VERSION ""

NS_ :

BS_:

BU_: SBG C125

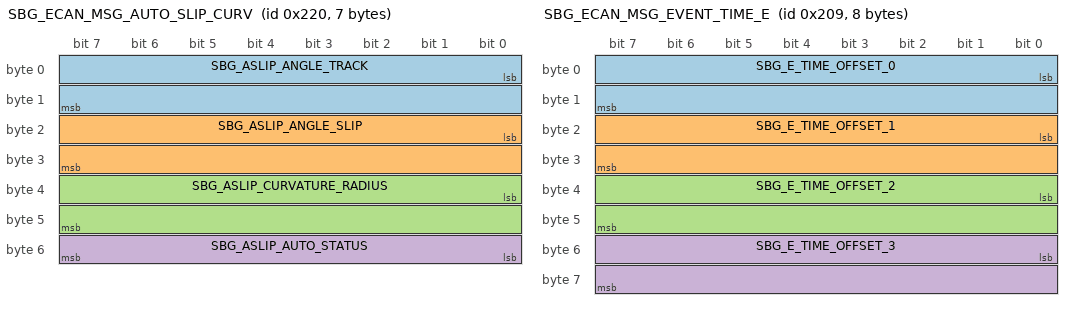
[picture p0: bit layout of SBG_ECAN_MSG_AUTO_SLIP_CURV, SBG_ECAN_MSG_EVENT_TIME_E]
BO_ 544 SBG_ECAN_MSG_AUTO_SLIP_CURV: 7 SBG
 SG_ SBG_ASLIP_ANGLE_TRACK : 0|16@1- (0.0001,0) [-3.2768|3.2767] "rad" C125
 SG_ SBG_ASLIP_ANGLE_SLIP : 16|16@1- (0.0001,0) [-3.2768|3.2767] "rad" C125
 SG_ SBG_ASLIP_CURVATURE_RADIUS : 32|16@1+ (0.01,0) [0|655.35] "m" C125
 SG_ SBG_ASLIP_AUTO_STATUS : 48|8@1+ (1,0) [0|255] "" C125

BO_ 521 SBG_ECAN_MSG_EVENT_TIME_E: 8 SBG
 SG_ SBG_E_TIME_OFFSET_0 : 0|16@1+ (1,0) [0|65535] "µs" Vector__XXX
 SG_ SBG_E_TIME_OFFSET_1 : 16|16@1+ (1,0) [0|65535] "µs" Vector__XXX
 SG_ SBG_E_TIME_OFFSET_2 : 32|16@1+ (1,0) [0|65535] "µs" Vector__XXX
 SG_ SBG_E_TIME_OFFSET_3 : 48|16@1+ (1,0) [0|65535] "µs" Vector__XXX

BO_ 520 SBG_ECAN_MSG_EVENT_INFO_E: 8 SBG
 SG_ SBG_E_TIME_STAMP : 0|32@1+ (1,0) [0|4294970000] "µs" Vector__XXX
 SG_ SBG_E_STATUS : 32|16@1+ (1,0) [0|65535] "" Vector__XXX

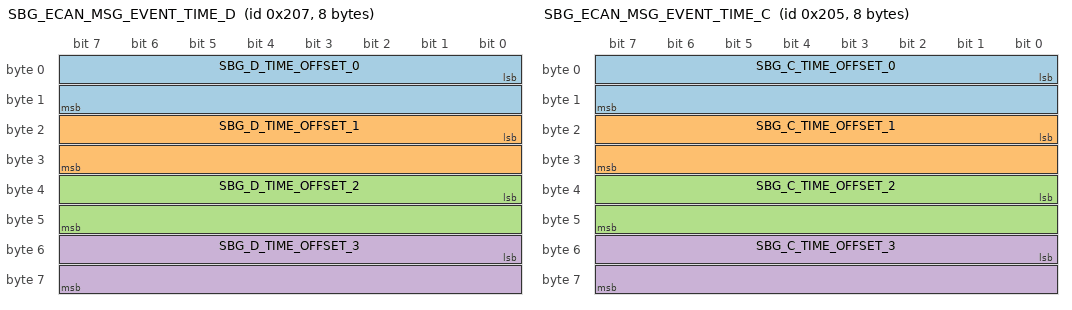
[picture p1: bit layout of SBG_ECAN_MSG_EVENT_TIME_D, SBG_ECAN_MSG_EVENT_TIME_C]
BO_ 519 SBG_ECAN_MSG_EVENT_TIME_D: 8 SBG
 SG_ SBG_D_TIME_OFFSET_0 : 0|16@1+ (1,0) [0|65535] "µs" Vector__XXX
 SG_ SBG_D_TIME_OFFSET_1 : 16|16@1+ (1,0) [0|65535] "µs" Vector__XXX
 SG_ SBG_D_TIME_OFFSET_2 : 32|16@1+ (1,0) [0|65535] "µs" Vector__XXX
 SG_ SBG_D_TIME_OFFSET_3 : 48|16@1+ (1,0) [0|65535] "µs" Vector__XXX

BO_ 518 SBG_ECAN_MSG_EVENT_INFO_D: 8 SBG
 SG_ SBG_D_TIME_STAMP : 0|32@1+ (1,0) [0|4294970000] "µs" Vector__XXX
 SG_ SBG_D_STATUS : 32|16@1+ (1,0) [0|65535] "" Vector__XXX

BO_ 517 SBG_ECAN_MSG_EVENT_TIME_C: 8 SBG
 SG_ SBG_C_TIME_OFFSET_0 : 0|16@1+ (1,0) [0|65535] "µs" Vector__XXX
 SG_ SBG_C_TIME_OFFSET_1 : 16|16@1+ (1,0) [0|65535] "µs" Vector__XXX
 SG_ SBG_C_TIME_OFFSET_2 : 32|16@1+ (1,0) [0|65535] "µs" Vector__XXX
 SG_ SBG_C_TIME_OFFSET_3 : 48|16@1+ (1,0) [0|65535] "µs" Vector__XXX

BO_ 516 SBG_ECAN_MSG_EVENT_INFO_C: 8 SBG
 SG_ SBG_C_TIME_STAMP : 0|32@1+ (1,0) [0|4294970000] "µs" Vector__XXX
 SG_ SBG_C_STATUS : 32|16@1+ (1,0) [0|65535] "" Vector__XXX

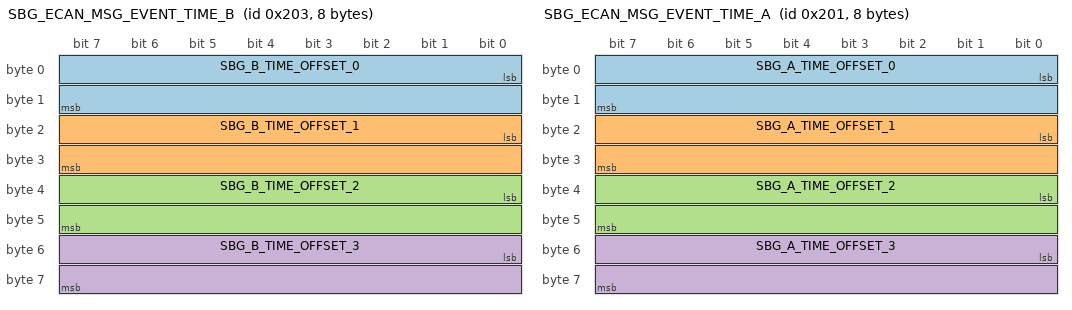
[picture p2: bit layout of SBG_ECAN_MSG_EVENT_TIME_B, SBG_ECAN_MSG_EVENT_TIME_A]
BO_ 515 SBG_ECAN_MSG_EVENT_TIME_B: 8 SBG
 SG_ SBG_B_TIME_OFFSET_0 : 0|16@1+ (1,0) [0|65535] "µs" Vector__XXX
 SG_ SBG_B_TIME_OFFSET_1 : 16|16@1+ (1,0) [0|65535] "µs" Vector__XXX
 SG_ SBG_B_TIME_OFFSET_2 : 32|16@1+ (1,0) [0|65535] "µs" Vector__XXX
 SG_ SBG_B_TIME_OFFSET_3 : 48|16@1+ (1,0) [0|65535] "µs" Vector__XXX

BO_ 514 SBG_ECAN_MSG_EVENT_INFO_B: 8 SBG
 SG_ SBG_B_TIME_STAMP : 0|32@1+ (1,0) [0|4294970000] "µs" Vector__XXX
 SG_ SBG_B_STATUS : 32|16@1+ (1,0) [0|65535] "" Vector__XXX

BO_ 513 SBG_ECAN_MSG_EVENT_TIME_A: 8 SBG
 SG_ SBG_A_TIME_OFFSET_0 : 0|16@1+ (1,0) [0|65535] "µs" Vector__XXX
 SG_ SBG_A_TIME_OFFSET_1 : 16|16@1+ (1,0) [0|65535] "µs" Vector__XXX
 SG_ SBG_A_TIME_OFFSET_2 : 32|16@1+ (1,0) [0|65535] "µs" Vector__XXX
 SG_ SBG_A_TIME_OFFSET_3 : 48|16@1+ (1,0) [0|65535] "µs" Vector__XXX

BO_ 512 SBG_ECAN_MSG_EVENT_INFO_A: 8 SBG
 SG_ SBG_A_TIME_STAMP : 0|32@1+ (1,0) [0|4294970000] "µs" Vector__XXX
 SG_ SBG_A_STATUS : 32|16@1+ (1,0) [0|65535] "" Vector__XXX

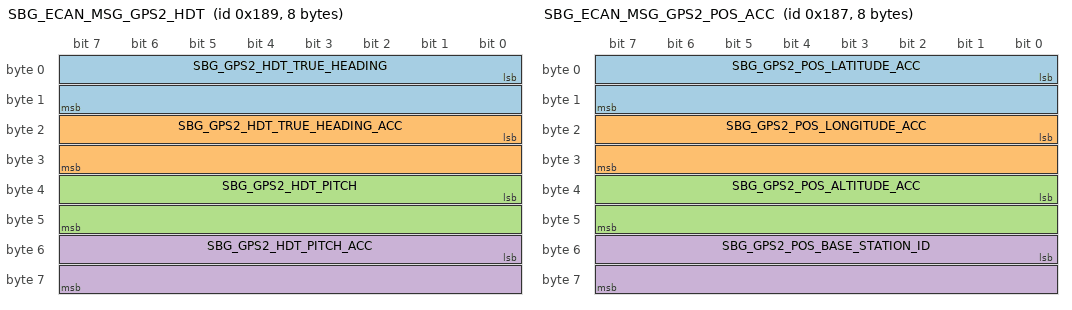
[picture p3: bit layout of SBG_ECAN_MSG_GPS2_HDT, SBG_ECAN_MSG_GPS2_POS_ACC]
BO_ 393 SBG_ECAN_MSG_GPS2_HDT: 8 SBG
 SG_ SBG_GPS2_HDT_TRUE_HEADING : 0|16@1+ (0.01,0) [0|655.35] "°" Vector__XXX
 SG_ SBG_GPS2_HDT_TRUE_HEADING_ACC : 16|16@1+ (0.01,0) [0|655.35] "°" Vector__XXX
 SG_ SBG_GPS2_HDT_PITCH : 32|16@1- (0.01,0) [-327.68|327.67] "°" Vector__XXX
 SG_ SBG_GPS2_HDT_PITCH_ACC : 48|16@1+ (0.01,0) [0|655.35] "°" Vector__XXX

BO_ 392 SBG_ECAN_MSG_GPS2_HDT_INFO: 6 SBG
 SG_ SBG_GPS2_HDT_TIME_STAMP : 0|32@1+ (1,0) [0|4294970000] "µs" Vector__XXX
 SG_ SBG_GPS2_HDT_STATUS : 32|16@1+ (1,0) [0|65535] "" Vector__XXX

BO_ 391 SBG_ECAN_MSG_GPS2_POS_ACC: 8 SBG
 SG_ SBG_GPS2_POS_LATITUDE_ACC : 0|16@1+ (0.01,0) [0|655.35] "m" Vector__XXX
 SG_ SBG_GPS2_POS_LONGITUDE_ACC : 16|16@1+ (0.01,0) [0|655.35] "m" Vector__XXX
 SG_ SBG_GPS2_POS_ALTITUDE_ACC : 32|16@1+ (0.01,0) [0|655.35] "m" Vector__XXX
 SG_ SBG_GPS2_POS_BASE_STATION_ID : 48|16@1+ (1,0) [0|65535] "" Vector__XXX

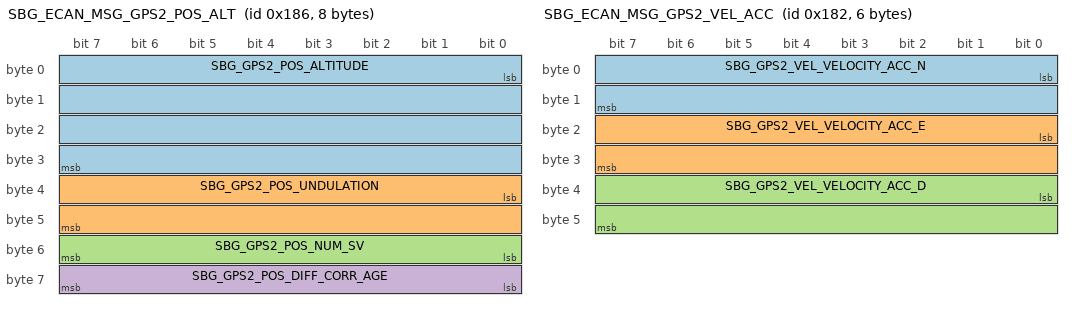
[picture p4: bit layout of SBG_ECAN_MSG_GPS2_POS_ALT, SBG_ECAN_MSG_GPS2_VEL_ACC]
BO_ 390 SBG_ECAN_MSG_GPS2_POS_ALT: 8 SBG
 SG_ SBG_GPS2_POS_ALTITUDE : 0|32@1- (0.001,0) [-2147480|2147480] "m" Vector__XXX
 SG_ SBG_GPS2_POS_UNDULATION : 32|16@1- (0.005,0) [-163.84|163.835] "m" Vector__XXX
 SG_ SBG_GPS2_POS_NUM_SV : 48|8@1+ (1,0) [0|255] "" Vector__XXX
 SG_ SBG_GPS2_POS_DIFF_CORR_AGE : 56|8@1+ (1,0) [0|255] "s" Vector__XXX

BO_ 389 SBG_ECAN_MSG_GPS2_POS: 8 SBG
 SG_ SBG_GPS2_POS_LATITUDE : 0|32@1- (0.0000001,0) [-214.7483648|214.7483647] "°" Vector__XXX
 SG_ SBG_GPS2_POS_LONGITUDE : 32|32@1- (0.0000001,0) [-214.7483648|214.7483647] "°" Vector__XXX

BO_ 388 SBG_ECAN_MSG_GPS2_POS_INFO: 8 SBG
 SG_ SGB_GPS2_POS_TIME_STAMP : 0|32@1+ (1,0) [0|4294970000] "µs" Vector__XXX
 SG_ SBG_GPS2_POS_STATUS : 32|32@1+ (1,0) [0|4294970000] "" Vector__XXX

BO_ 387 SBG_ECAN_MSG_GPS2_VEL_COURSE: 4 SBG
 SG_ SBG_GPS2_VEL_COURSE : 0|16@1+ (0.01,0) [0|655.35] "°" Vector__XXX
 SG_ SBG_GPS2_VEL_COURSE_ACC : 16|16@1+ (0.01,0) [0|655.35] "°" Vector__XXX

BO_ 386 SBG_ECAN_MSG_GPS2_VEL_ACC: 6 SBG
 SG_ SBG_GPS2_VEL_VELOCITY_ACC_N : 0|16@1- (0.01,0) [-327.68|327.67] "m.s-1" Vector__XXX
 SG_ SBG_GPS2_VEL_VELOCITY_ACC_E : 16|16@1- (0.01,0) [-327.68|327.67] "m.s-1" Vector__XXX
 SG_ SBG_GPS2_VEL_VELOCITY_ACC_D : 32|16@1- (0.01,0) [-327.68|327.67] "m.s-1" Vector__XXX

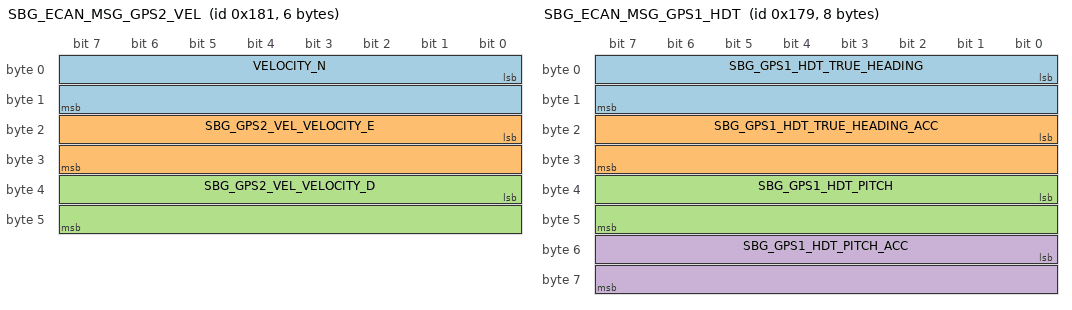
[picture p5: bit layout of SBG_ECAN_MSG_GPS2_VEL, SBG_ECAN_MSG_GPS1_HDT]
BO_ 385 SBG_ECAN_MSG_GPS2_VEL: 6 SBG
 SG_ VELOCITY_N : 0|16@1- (0.01,0) [-327.68|327.67] "m.s-1" Vector__XXX
 SG_ SBG_GPS2_VEL_VELOCITY_E : 16|16@1- (0.01,0) [-327.68|327.67] "m.s-1" Vector__XXX
 SG_ SBG_GPS2_VEL_VELOCITY_D : 32|16@1- (0.01,0) [-327.68|327.67] "m.s-1" Vector__XXX

BO_ 384 SBG_ECAN_MSG_GPS2_VEL_INFO: 8 SBG
 SG_ SBG_GPS2_VEL_TIME_STAMP : 0|32@1+ (1,0) [0|4294970000] "µs" Vector__XXX
 SG_ SBG_GPS2_VEL_STATUS : 32|32@1+ (1,0) [0|4294970000] "" Vector__XXX

BO_ 377 SBG_ECAN_MSG_GPS1_HDT: 8 SBG
 SG_ SBG_GPS1_HDT_TRUE_HEADING : 0|16@1+ (0.01,0) [0|655.35] "°" Vector__XXX
 SG_ SBG_GPS1_HDT_TRUE_HEADING_ACC : 16|16@1+ (0.01,0) [0|655.35] "°" Vector__XXX
 SG_ SBG_GPS1_HDT_PITCH : 32|16@1- (0.01,0) [-327.68|327.67] "°" Vector__XXX
 SG_ SBG_GPS1_HDT_PITCH_ACC : 48|16@1+ (0.01,0) [0|655.35] "°" Vector__XXX

BO_ 376 SBG_ECAN_MSG_GPS1_HDT_INFO: 6 SBG
 SG_ SBG_GPS1_HDT_TIME_STAMP : 0|32@1+ (1,0) [0|4294970000] "µs" Vector__XXX
 SG_ SBG_GPS1_HDT_STATUS : 32|16@1+ (1,0) [0|65535] "" Vector__XXX

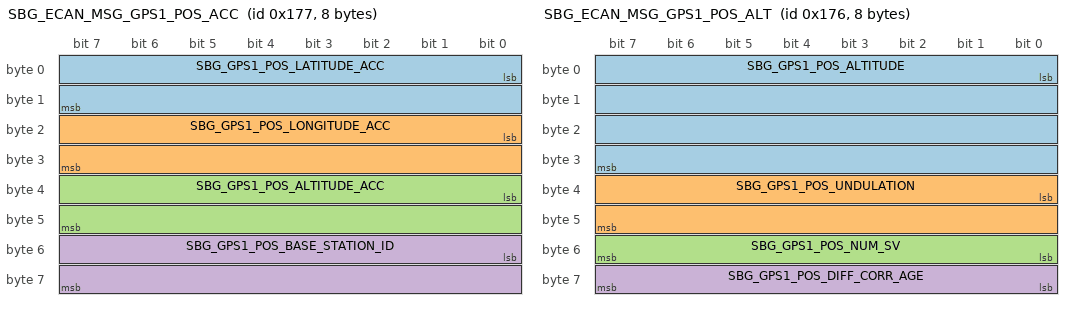
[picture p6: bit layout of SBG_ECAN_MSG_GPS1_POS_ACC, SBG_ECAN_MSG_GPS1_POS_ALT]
BO_ 375 SBG_ECAN_MSG_GPS1_POS_ACC: 8 SBG
 SG_ SBG_GPS1_POS_LATITUDE_ACC : 0|16@1+ (0.01,0) [0|655.35] "m" Vector__XXX
 SG_ SBG_GPS1_POS_LONGITUDE_ACC : 16|16@1+ (0.01,0) [0|655.35] "m" Vector__XXX
 SG_ SBG_GPS1_POS_ALTITUDE_ACC : 32|16@1+ (0.01,0) [0|655.35] "m" Vector__XXX
 SG_ SBG_GPS1_POS_BASE_STATION_ID : 48|16@1+ (1,0) [0|65535] "" Vector__XXX

BO_ 374 SBG_ECAN_MSG_GPS1_POS_ALT: 8 SBG
 SG_ SBG_GPS1_POS_ALTITUDE : 0|32@1- (0.001,0) [-2147480|2147480] "m" Vector__XXX
 SG_ SBG_GPS1_POS_UNDULATION : 32|16@1- (0.005,0) [-163.84|163.835] "m" Vector__XXX
 SG_ SBG_GPS1_POS_NUM_SV : 48|8@1+ (1,0) [0|255] "" Vector__XXX
 SG_ SBG_GPS1_POS_DIFF_CORR_AGE : 56|8@1+ (1,0) [0|255] "s" Vector__XXX

BO_ 373 SBG_ECAN_MSG_GPS1_POS: 8 SBG
 SG_ SBG_GPS1_POS_LATITUDE : 0|32@1- (0.0000001,0) [-214.7483648|214.7483647] "°" C125
 SG_ SBG_GPS1_POS_LONGITUDE : 32|32@1- (0.0000001,0) [-214.7483648|214.7483647] "°" C125

BO_ 372 SBG_ECAN_MSG_GPS1_POS_INFO: 8 SBG
 SG_ SBG_GPS1_POS_TIME_STAMP : 0|32@1+ (1,0) [0|4294970000] "µs" Vector__XXX
 SG_ SBG_GPS1_POS_STATUS : 32|32@1+ (1,0) [0|4294970000] "" Vector__XXX

BO_ 371 SBG_ECAN_MSG_GPS1_VEL_COURSE: 4 SBG
 SG_ SBG_GPS1_VEL_COURSE : 0|16@1+ (0.01,0) [0|655.35] "°" Vector__XXX
 SG_ SBG_GPS1_VEL_COURSE_ACC : 16|16@1+ (0.01,0) [0|655.35] "°" Vector__XXX

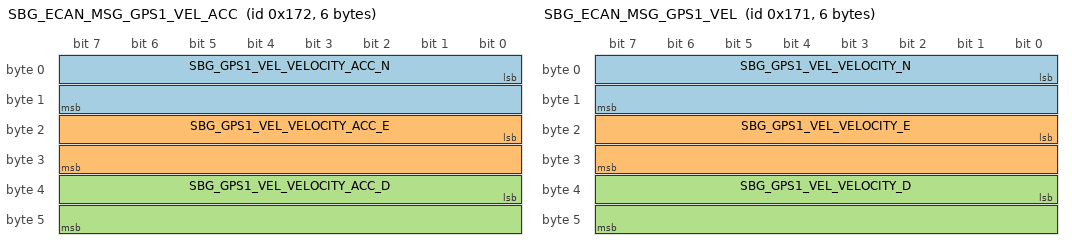
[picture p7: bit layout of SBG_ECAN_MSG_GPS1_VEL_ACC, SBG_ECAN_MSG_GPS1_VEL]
BO_ 370 SBG_ECAN_MSG_GPS1_VEL_ACC: 6 SBG
 SG_ SBG_GPS1_VEL_VELOCITY_ACC_N : 0|16@1- (0.01,0) [-327.68|327.67] "m.s-1" Vector__XXX
 SG_ SBG_GPS1_VEL_VELOCITY_ACC_E : 16|16@1- (0.01,0) [-327.68|327.67] "m.s-1" Vector__XXX
 SG_ SBG_GPS1_VEL_VELOCITY_ACC_D : 32|16@1- (0.01,0) [-327.68|327.67] "m.s-1" Vector__XXX

BO_ 369 SBG_ECAN_MSG_GPS1_VEL: 6 SBG
 SG_ SBG_GPS1_VEL_VELOCITY_N : 0|16@1- (0.01,0) [-327.68|327.67] "m.s-1" C125
 SG_ SBG_GPS1_VEL_VELOCITY_E : 16|16@1- (0.01,0) [-327.68|327.67] "m.s-1" C125
 SG_ SBG_GPS1_VEL_VELOCITY_D : 32|16@1- (0.01,0) [-327.68|327.67] "m.s-1" C125

BO_ 368 SBG_ECAN_MSG_GPS1_VEL_INFO: 8 SBG
 SG_ SBG_GPS1_VEL_TIME_STAMP : 0|32@1+ (1,0) [0|4294970000] "µs" Vector__XXX
 SG_ SBG_GPS1_VEL_STATUS : 32|32@1+ (1,0) [0|4294970000] "" Vector__XXX

BO_ 359 SBG_ECAN_MSG_DEPTH_ALTITUDE: 8 SBG
 SG_ SBG_DEPTH_PRESSURE_ABS : 0|32@1+ (0.1,0) [0|429497000] "Pa" Vector__XXX
 SG_ SBG_DEPTH_DEPTH : 32|32@1- (0.001,0) [-2147480|2147480] "m" Vector__XXX

BO_ 358 SBG_ECAN_MSG_DEPTH_INFO: 5 SBG
 SG_ SBG_DEPTH_TIME_STAMP : 0|32@1+ (1,0) [0|4294970000] "us" Vector__XXX
 SG_ SBG_DEPTH_DEPTH_STATUS : 32|8@1+ (1,0) [0|255] "" Vector__XXX

BO_ 356 SBG_ECAN_MSG_AIR_DATA_AIRSPEED: 6 SBG
 SG_ SBG_AIR_PRESSURE_DIFF : 0|32@1- (0.001,0) [-2147483.648|2147483.6469999999] "Pa" Vector__XXX
 SG_ SBG_AIR_AIRSPEED : 32|16@1- (0.01,0) [-327.68|327.67] "m.s-1" Vector__XXX

BO_ 355 SBG_ECAN_MSG_AIR_DATA_ALTITUDE: 8 SBG
 SG_ SBG_AIR_PRESSURE_ABS : 0|32@1+ (0.001,0) [0|4294967.2949999999] "Pa" Vector__XXX
 SG_ SBG_AIR_ALTITUDE : 32|32@1- (0.001,0) [-2147483.648|2147483.6469999999] "m" Vector__XXX

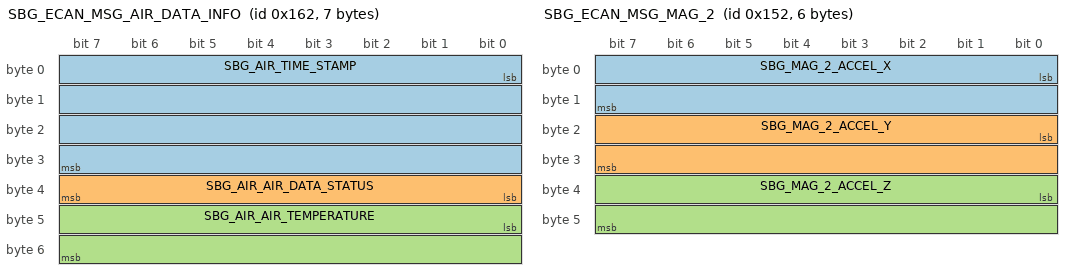
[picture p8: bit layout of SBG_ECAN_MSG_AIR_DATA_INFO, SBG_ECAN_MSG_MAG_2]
BO_ 354 SBG_ECAN_MSG_AIR_DATA_INFO: 7 SBG
 SG_ SBG_AIR_TIME_STAMP : 0|32@1+ (1,0) [0|4294970000] "us" Vector__XXX
 SG_ SBG_AIR_AIR_DATA_STATUS : 32|8@1+ (1,0) [0|255] "" Vector__XXX
 SG_ SBG_AIR_AIR_TEMPERATURE : 40|16@1- (0.01,0) [-327.68|327.67] "°C" Vector__XXX

BO_ 353 SBG_ECAN_MSG_ODO_VEL: 2 SBG
 SG_ SBG_ODO_VELOCITY : 0|16@1- (0.01,0) [-327.68|327.67] "m.s-1" Vector__XXX

BO_ 352 SBG_ECAN_MSG_ODO_INFO: 6 SBG
 SG_ SBG_ODO_TIME_STAMP : 0|32@1+ (1,0) [0|4294970000] "µs" Vector__XXX
 SG_ SBG_ODO_ODO_STATUS : 32|16@1+ (1,0) [0|65535] "" Vector__XXX

BO_ 338 SBG_ECAN_MSG_MAG_2: 6 SBG
 SG_ SBG_MAG_2_ACCEL_X : 0|16@1- (0.01,0) [-327.68|327.67] "m.s-2" Vector__XXX
 SG_ SBG_MAG_2_ACCEL_Y : 16|16@1- (0.01,0) [-327.68|327.67] "m.s-2" Vector__XXX
 SG_ SBG_MAG_2_ACCEL_Z : 32|16@1- (0.01,0) [-327.68|327.67] "m.s-2" Vector__XXX

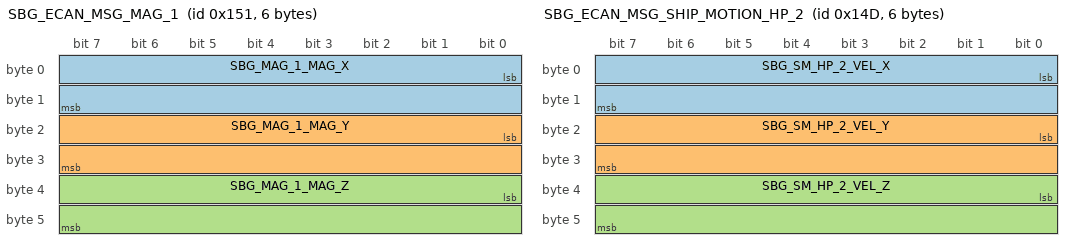
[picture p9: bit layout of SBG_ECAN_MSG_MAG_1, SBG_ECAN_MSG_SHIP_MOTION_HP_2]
BO_ 337 SBG_ECAN_MSG_MAG_1: 6 SBG
 SG_ SBG_MAG_1_MAG_X : 0|16@1- (0.001,0) [-32.768|32.767] "a.u." Vector__XXX
 SG_ SBG_MAG_1_MAG_Y : 16|16@1- (0.001,0) [-32.768|32.767] "a.u." Vector__XXX
 SG_ SBG_MAG_1_MAG_Z : 32|16@1- (0.001,0) [-32.768|32.767] "a.u." Vector__XXX

BO_ 336 SBG_ECAN_MSG_MAG_0: 6 SBG
 SG_ SBG_MAG_0_TIME_STAMP : 0|32@1+ (1,0) [0|4294970000] "µs" Vector__XXX
 SG_ SBG_MAG_0_STATUS : 32|16@1+ (1,0) [0|65535] "" Vector__XXX

BO_ 333 SBG_ECAN_MSG_SHIP_MOTION_HP_2: 6 SBG
 SG_ SBG_SM_HP_2_VEL_X : 0|16@1- (0.01,0) [-327.68|327.67] "m.s-1" Vector__XXX
 SG_ SBG_SM_HP_2_VEL_Y : 16|16@1- (0.01,0) [-327.68|327.67] "m.s-1" Vector__XXX
 SG_ SBG_SM_HP_2_VEL_Z : 32|16@1- (0.01,0) [-327.68|327.67] "m.s-1" Vector__XXX

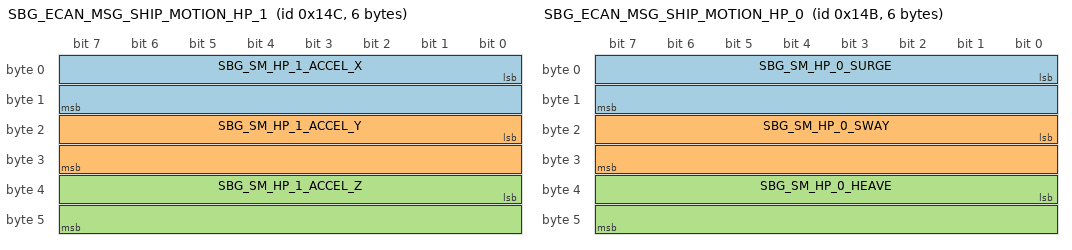
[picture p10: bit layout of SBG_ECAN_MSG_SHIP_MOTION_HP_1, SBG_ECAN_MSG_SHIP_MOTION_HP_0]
BO_ 332 SBG_ECAN_MSG_SHIP_MOTION_HP_1: 6 SBG
 SG_ SBG_SM_HP_1_ACCEL_X : 0|16@1- (0.01,0) [-327.68|327.67] "m.s-2" Vector__XXX
 SG_ SBG_SM_HP_1_ACCEL_Y : 16|16@1- (0.01,0) [-327.68|327.67] "m.s-2" Vector__XXX
 SG_ SBG_SM_HP_1_ACCEL_Z : 32|16@1- (0.01,0) [-327.68|327.67] "m.s-2" Vector__XXX

BO_ 331 SBG_ECAN_MSG_SHIP_MOTION_HP_0: 6 SBG
 SG_ SBG_SM_HP_0_SURGE : 0|16@1- (0.001,0) [-32.768|32.767] "m" Vector__XXX
 SG_ SBG_SM_HP_0_SWAY : 16|16@1- (0.001,0) [-32.768|32.767] "m" Vector__XXX
 SG_ SBG_SM_HP_0_HEAVE : 32|16@1- (0.001,0) [-32.768|32.767] "m" Vector__XXX

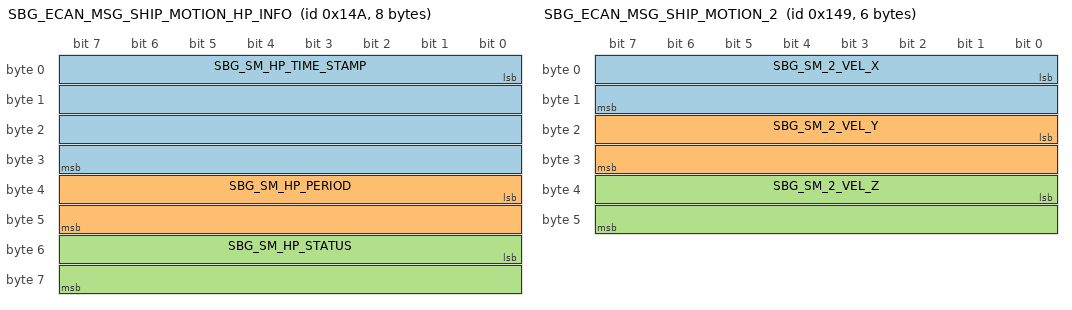
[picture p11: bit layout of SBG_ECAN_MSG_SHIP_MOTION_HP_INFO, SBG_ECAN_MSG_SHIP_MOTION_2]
BO_ 330 SBG_ECAN_MSG_SHIP_MOTION_HP_INFO: 8 SBG
 SG_ SBG_SM_HP_TIME_STAMP : 0|32@1+ (1,0) [0|4294970000] "µs" Vector__XXX
 SG_ SBG_SM_HP_PERIOD : 32|16@1+ (0.01,0) [0|655.35] "s" Vector__XXX
 SG_ SBG_SM_HP_STATUS : 48|16@1+ (1,0) [0|65535] "" Vector__XXX

BO_ 329 SBG_ECAN_MSG_SHIP_MOTION_2: 6 SBG
 SG_ SBG_SM_2_VEL_X : 0|16@1- (0.01,0) [-327.68|327.67] "m.s-1" Vector__XXX
 SG_ SBG_SM_2_VEL_Y : 16|16@1- (0.01,0) [-327.68|327.67] "m.s-1" Vector__XXX
 SG_ SBG_SM_2_VEL_Z : 32|16@1- (0.01,0) [-327.68|327.67] "m.s-1" Vector__XXX

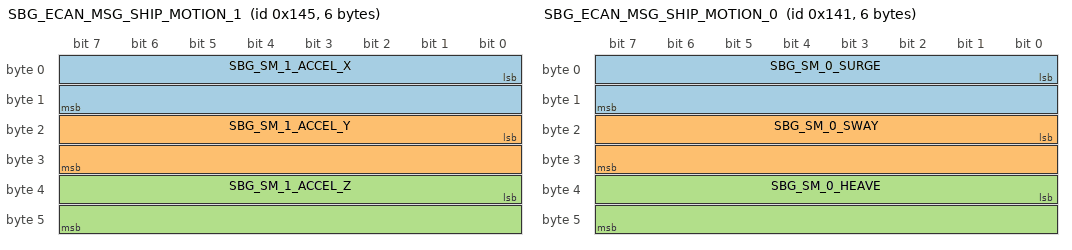
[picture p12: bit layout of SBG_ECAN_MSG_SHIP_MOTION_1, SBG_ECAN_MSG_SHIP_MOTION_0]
BO_ 325 SBG_ECAN_MSG_SHIP_MOTION_1: 6 SBG
 SG_ SBG_SM_1_ACCEL_X : 0|16@1- (0.01,0) [-327.68|327.67] "m.s-2" Vector__XXX
 SG_ SBG_SM_1_ACCEL_Y : 16|16@1- (0.01,0) [-327.68|327.67] "m.s-2" Vector__XXX
 SG_ SBG_SM_1_ACCEL_Z : 32|16@1- (0.01,0) [-327.68|327.67] "m.s-2" Vector__XXX

BO_ 321 SBG_ECAN_MSG_SHIP_MOTION_0: 6 SBG
 SG_ SBG_SM_0_SURGE : 0|16@1- (0.001,0) [-32.768|32.767] "m" Vector__XXX
 SG_ SBG_SM_0_SWAY : 16|16@1- (0.001,0) [-32.768|32.767] "m" Vector__XXX
 SG_ SBG_SM_0_HEAVE : 32|16@1- (0.001,0) [-32.768|32.767] "m" Vector__XXX

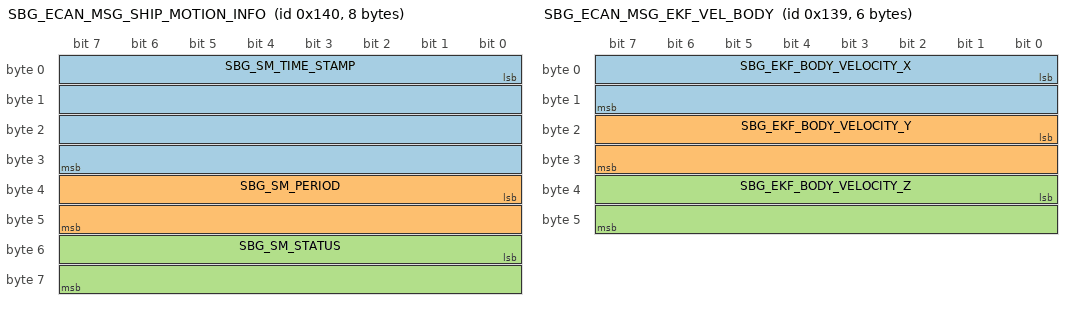
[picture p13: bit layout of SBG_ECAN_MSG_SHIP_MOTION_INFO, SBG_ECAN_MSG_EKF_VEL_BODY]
BO_ 320 SBG_ECAN_MSG_SHIP_MOTION_INFO: 8 SBG
 SG_ SBG_SM_TIME_STAMP : 0|32@1+ (1,0) [0|4294970000] "µs" Vector__XXX
 SG_ SBG_SM_PERIOD : 32|16@1+ (0.01,0) [0|655.35] "s" Vector__XXX
 SG_ SBG_SM_STATUS : 48|16@1+ (1,0) [0|65535] "" Vector__XXX

BO_ 313 SBG_ECAN_MSG_EKF_VEL_BODY: 6 SBG
 SG_ SBG_EKF_BODY_VELOCITY_X : 0|16@1- (0.01,0) [-327.68|327.67] "m.s-1" C125
 SG_ SBG_EKF_BODY_VELOCITY_Y : 16|16@1- (0.01,0) [-327.68|327.67] "m.s-1" C125
 SG_ SBG_EKF_BODY_VELOCITY_Z : 32|16@1- (0.01,0) [-327.68|327.67] "m.s-1" C125

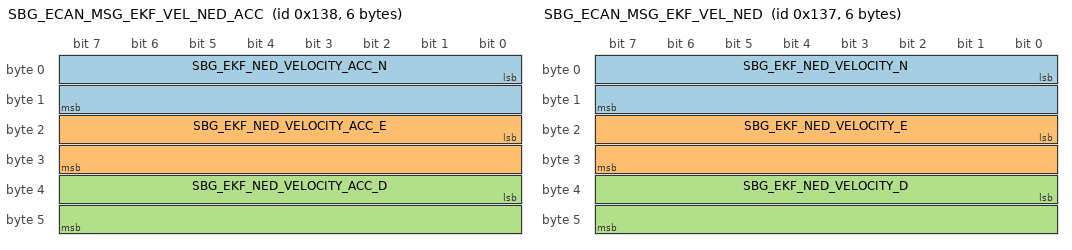
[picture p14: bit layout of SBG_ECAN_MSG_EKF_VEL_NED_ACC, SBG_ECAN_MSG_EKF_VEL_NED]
BO_ 312 SBG_ECAN_MSG_EKF_VEL_NED_ACC: 6 SBG
 SG_ SBG_EKF_NED_VELOCITY_ACC_N : 0|16@1- (0.01,0) [-327.68|327.67] "m.s-1" Vector__XXX
 SG_ SBG_EKF_NED_VELOCITY_ACC_E : 16|16@1- (0.01,0) [-327.68|327.67] "m.s-1" Vector__XXX
 SG_ SBG_EKF_NED_VELOCITY_ACC_D : 32|16@1- (0.01,0) [-327.68|327.67] "m.s-1" Vector__XXX

BO_ 311 SBG_ECAN_MSG_EKF_VEL_NED: 6 SBG
 SG_ SBG_EKF_NED_VELOCITY_N : 0|16@1- (0.01,0) [-327.68|327.67] "m.s-1" C125
 SG_ SBG_EKF_NED_VELOCITY_E : 16|16@1- (0.01,0) [-327.68|327.67] "m.s-1" C125
 SG_ SBG_EKF_NED_VELOCITY_D : 32|16@1- (0.01,0) [-327.68|327.67] "m.s-1" C125

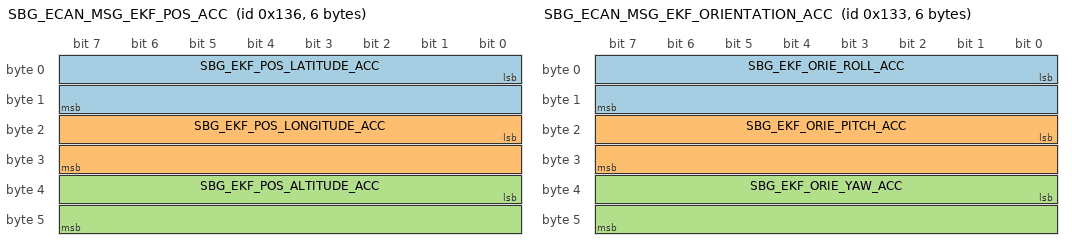
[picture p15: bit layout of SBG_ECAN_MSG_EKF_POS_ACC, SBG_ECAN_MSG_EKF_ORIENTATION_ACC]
BO_ 310 SBG_ECAN_MSG_EKF_POS_ACC: 6 SBG
 SG_ SBG_EKF_POS_LATITUDE_ACC : 0|16@1+ (0.01,0) [0|655.35] "m" Vector__XXX
 SG_ SBG_EKF_POS_LONGITUDE_ACC : 16|16@1+ (0.01,0) [0|655.35] "m" Vector__XXX
 SG_ SBG_EKF_POS_ALTITUDE_ACC : 32|16@1+ (0.01,0) [0|655.35] "m" Vector__XXX

BO_ 309 SBG_ECAN_MSG_EKF_ALTITUDE: 6 SBG
 SG_ SBG_EKF_ALTITUDE : 0|32@1- (0.001,0) [-2147480|2147480] "m" C125
 SG_ SBG_EKF_UNDULATION : 32|16@1- (0.005,0) [-163.84|163.835] "m" C125

BO_ 308 SBG_ECAN_MSG_EKF_POS: 8 SBG
 SG_ SBG_EKF_POS_LATITUDE : 0|32@1- (0.0000001,0) [-214.7483648|214.7483647] "°" C125
 SG_ SBG_EKF_POS_LONGITUDE : 32|32@1- (0.0000001,0) [-214.7483648|214.7483647] "°" C125

BO_ 307 SBG_ECAN_MSG_EKF_ORIENTATION_ACC: 6 SBG
 SG_ SBG_EKF_ORIE_ROLL_ACC : 0|16@1+ (0.0001,0) [0|6.5535] "rad" Vector__XXX
 SG_ SBG_EKF_ORIE_PITCH_ACC : 16|16@1+ (0.0001,0) [0|6.5535] "rad" Vector__XXX
 SG_ SBG_EKF_ORIE_YAW_ACC : 32|16@1+ (0.0001,0) [0|6.5535] "rad" Vector__XXX

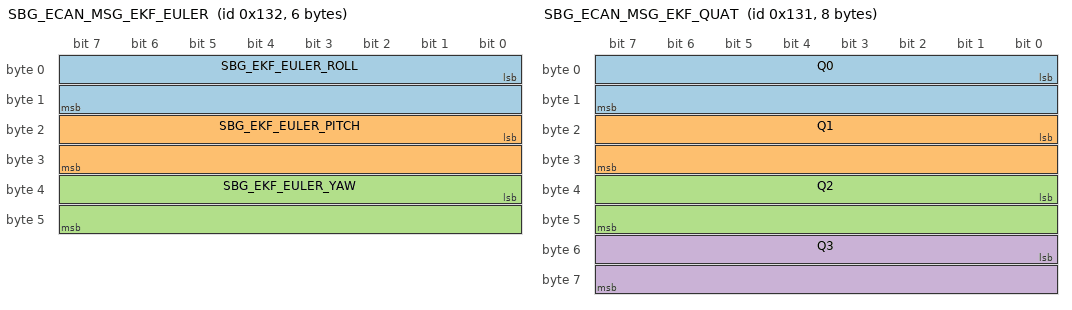
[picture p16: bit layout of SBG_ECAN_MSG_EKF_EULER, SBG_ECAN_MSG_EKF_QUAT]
BO_ 306 SBG_ECAN_MSG_EKF_EULER: 6 SBG
 SG_ SBG_EKF_EULER_ROLL : 0|16@1- (0.0001,0) [-3.2768|3.2767] "rad" C125
 SG_ SBG_EKF_EULER_PITCH : 16|16@1- (0.0001,0) [-3.2768|3.2767] "rad" C125
 SG_ SBG_EKF_EULER_YAW : 32|16@1- (0.0001,0) [-3.2768|3.2767] "rad" C125

BO_ 305 SBG_ECAN_MSG_EKF_QUAT: 8 SBG
 SG_ Q0 : 0|16@1- (0.0000305185,0) [-1|1] "" Vector__XXX
 SG_ Q1 : 16|16@1- (0.0000305185,0) [-1|1] "" Vector__XXX
 SG_ Q2 : 32|16@1- (0.0000305185,0) [-1|1] "" Vector__XXX
 SG_ Q3 : 48|16@1- (0.0000305185,0) [-1|1] "" Vector__XXX

BO_ 304 SBG_ECAN_MSG_EKF_INFO: 4 SBG
 SG_ SBG_EFK_TIME_STAMP : 0|32@1+ (1,0) [0|4294970000] "µs" C125

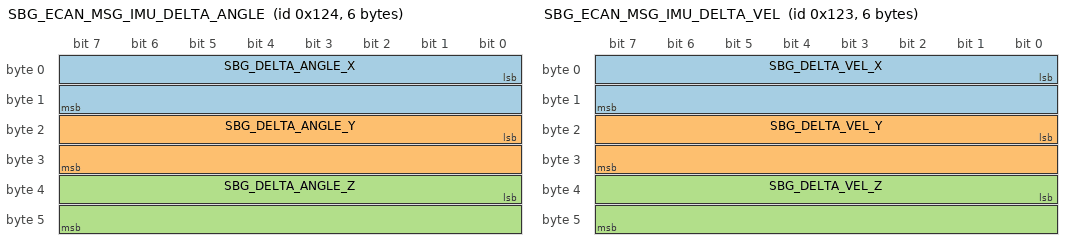
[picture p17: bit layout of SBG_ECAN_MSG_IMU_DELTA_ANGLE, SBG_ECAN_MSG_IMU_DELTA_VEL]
BO_ 292 SBG_ECAN_MSG_IMU_DELTA_ANGLE: 6 SBG
 SG_ SBG_DELTA_ANGLE_X : 0|16@1- (0.001,0) [-32.768|32.767] "rad.s-1" Vector__XXX
 SG_ SBG_DELTA_ANGLE_Y : 16|16@1- (0.001,0) [-32.768|32.767] "rad.s-1" Vector__XXX
 SG_ SBG_DELTA_ANGLE_Z : 32|16@1- (0.001,0) [-32.768|32.767] "rad.s-1" Vector__XXX

BO_ 291 SBG_ECAN_MSG_IMU_DELTA_VEL: 6 SBG
 SG_ SBG_DELTA_VEL_X : 0|16@1- (0.01,0) [-327.68|327.67] "m.s-2" Vector__XXX
 SG_ SBG_DELTA_VEL_Y : 16|16@1- (0.01,0) [-327.68|327.67] "m.s-2" Vector__XXX
 SG_ SBG_DELTA_VEL_Z : 32|16@1- (0.01,0) [-327.68|327.67] "m.s-2" Vector__XXX

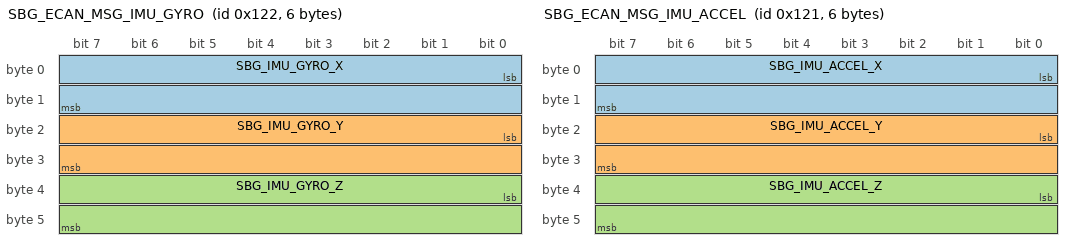
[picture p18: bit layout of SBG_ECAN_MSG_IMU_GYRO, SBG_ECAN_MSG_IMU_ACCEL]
BO_ 290 SBG_ECAN_MSG_IMU_GYRO: 6 SBG
 SG_ SBG_IMU_GYRO_X : 0|16@1- (0.001,0) [-32.768|32.767] "rad.s-1" C125
 SG_ SBG_IMU_GYRO_Y : 16|16@1- (0.001,0) [-32.768|32.767] "rad.s-1" C125
 SG_ SBG_IMU_GYRO_Z : 32|16@1- (0.001,0) [-32.768|32.767] "rad.s-1" C125

BO_ 289 SBG_ECAN_MSG_IMU_ACCEL: 6 SBG
 SG_ SBG_IMU_ACCEL_X : 0|16@1- (0.01,0) [-327.68|327.67] "m.s-2" C125
 SG_ SBG_IMU_ACCEL_Y : 16|16@1- (0.01,0) [-327.68|327.67] "m.s-2" C125
 SG_ SBG_IMU_ACCEL_Z : 32|16@1- (0.01,0) [-327.68|327.67] "m.s-2" C125

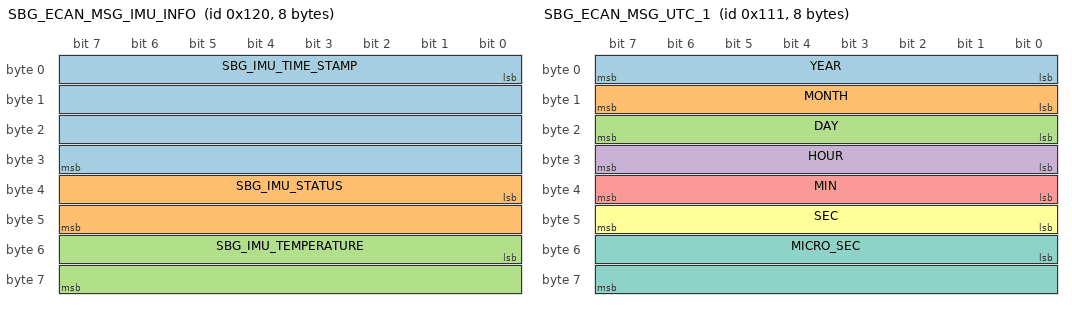
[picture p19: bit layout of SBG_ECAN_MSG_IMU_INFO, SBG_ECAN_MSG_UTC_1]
BO_ 288 SBG_ECAN_MSG_IMU_INFO: 8 SBG
 SG_ SBG_IMU_TIME_STAMP : 0|32@1+ (1,0) [0|4294970000] "µs" Vector__XXX
 SG_ SBG_IMU_STATUS : 32|16@1+ (1,0) [0|65535] "" Vector__XXX
 SG_ SBG_IMU_TEMPERATURE : 48|16@1- (0.01,0) [-327.68|327.67] "°C" Vector__XXX

BO_ 273 SBG_ECAN_MSG_UTC_1: 8 SBG
 SG_ YEAR : 0|8@1+ (1,2000) [2000|2255] "year" Vector__XXX
 SG_ MONTH : 8|8@1+ (1,0) [0|255] "month" Vector__XXX
 SG_ DAY : 16|8@1+ (1,0) [0|255] "d" Vector__XXX
 SG_ HOUR : 24|8@1+ (1,0) [0|255] "h" Vector__XXX
 SG_ MIN : 32|8@1+ (1,0) [0|255] "min" Vector__XXX
 SG_ SEC : 40|8@1+ (1,0) [0|255] "s" Vector__XXX
 SG_ MICRO_SEC : 48|16@1+ (100,0) [0|6553500] "us" Vector__XXX

BO_ 272 SBG_ECAN_MSG_UTC_0: 8 SBG
 SG_ SBG_UTC_0_TIME_STAMP : 0|32@1+ (1,0) [0|4294970000] "µs" Vector__XXX
 SG_ SBG_UTC_0_GPS_TOW : 32|32@1+ (1,0) [0|4294970000] "ms" Vector__XXX

BO_ 258 SBG_ECAN_MSG_STATUS_03: 6 SBG
 SG_ SBG_MSG_03_SOLUTION : 0|32@1+ (1,0) [0|4294970000] "" Vector__XXX
 SG_ SBG_MSG_03_HEAVE_STATUS : 32|16@1+ (1,0) [0|65535] "" Vector__XXX

BO_ 257 SBG_ECAN_MSG_STATUS_02: 8 SBG
 SG_ SBG_MSG_02_COM : 0|32@1+ (1,0) [0|4294970000] "" Vector__XXX
 SG_ SBG_MSG_02_AIDING : 32|32@1+ (1,0) [0|4294970000] "" Vector__XXX

BO_ 256 SBG_ECAN_MSG_STATUS_01: 8 SBG
 SG_ SBG_MSG_01_TIME_STAMP : 0|32@1+ (1,0) [0|4294970000] "µs" C125
 SG_ SBG_MSG_01_GENERAL : 32|16@1+ (1,0) [0|65535] "" C125
 SG_ SBG_MSG_01_CLOCK : 48|16@1+ (1,0) [0|65535] "" C125

BA_DEF_  "BusType" STRING ;
BA_DEF_  "DBName" STRING ;
BA_DEF_ BO_  "GenMsgCycleTime" INT 0 65535;
BA_DEF_ BO_  "SendType" STRING;
BA_DEF_ BO_  "RxTimeoutMs" INT 0 65535;
BA_DEF_ BO_  "MoTeC" STRING;
BA_DEF_ BO_  "Status" STRING;
BA_DEF_ BO_  "VFrameFormat" ENUM "StandardCAN","ExtendedCAN";
BA_DEF_DEF_  "BusType" "CAN";
BA_DEF_DEF_  "DBName" "";
BA_DEF_DEF_  "GenMsgCycleTime" 0;
BA_DEF_DEF_  "SendType" "Cyclic";
BA_DEF_DEF_  "RxTimeoutMs" 0;
BA_DEF_DEF_  "MoTeC" "No";
BA_DEF_DEF_  "Status" "Current";
BA_DEF_DEF_  "VFrameFormat" "StandardCAN";
BA_ "DBName" "sbg_ecan";
BA_ "GenMsgCycleTime" BO_ 544 20;
BA_ "RxTimeoutMs" BO_ 544 60;
BA_ "MoTeC" BO_ 544 "Yes";
BA_ "SendType" BO_ 521 "Event";
BA_ "SendType" BO_ 520 "Event";
BA_ "SendType" BO_ 519 "Event";
BA_ "SendType" BO_ 518 "Event";
BA_ "SendType" BO_ 517 "Event";
BA_ "SendType" BO_ 516 "Event";
BA_ "SendType" BO_ 515 "Event";
BA_ "SendType" BO_ 514 "Event";
BA_ "SendType" BO_ 513 "Event";
BA_ "SendType" BO_ 512 "Event";
BA_ "SendType" BO_ 393 "Event";
BA_ "SendType" BO_ 392 "Event";
BA_ "SendType" BO_ 391 "Event";
BA_ "SendType" BO_ 390 "Event";
BA_ "SendType" BO_ 389 "Event";
BA_ "SendType" BO_ 388 "Event";
BA_ "SendType" BO_ 387 "Event";
BA_ "SendType" BO_ 386 "Event";
BA_ "SendType" BO_ 385 "Event";
BA_ "SendType" BO_ 384 "Event";
BA_ "SendType" BO_ 377 "Event";
BA_ "SendType" BO_ 376 "Event";
BA_ "SendType" BO_ 375 "Event";
BA_ "SendType" BO_ 374 "Event";
BA_ "GenMsgCycleTime" BO_ 373 100;
BA_ "RxTimeoutMs" BO_ 373 300;
BA_ "MoTeC" BO_ 373 "Yes";
BA_ "SendType" BO_ 372 "Event";
BA_ "SendType" BO_ 371 "Event";
BA_ "SendType" BO_ 370 "Event";
BA_ "GenMsgCycleTime" BO_ 369 100;
BA_ "RxTimeoutMs" BO_ 369 300;
BA_ "MoTeC" BO_ 369 "Yes";
BA_ "SendType" BO_ 368 "Event";
BA_ "SendType" BO_ 359 "Event";
BA_ "SendType" BO_ 358 "Event";
BA_ "SendType" BO_ 356 "Event";
BA_ "SendType" BO_ 355 "Event";
BA_ "SendType" BO_ 354 "Event";
BA_ "SendType" BO_ 353 "Event";
BA_ "SendType" BO_ 352 "Event";
BA_ "SendType" BO_ 338 "Event";
BA_ "SendType" BO_ 337 "Event";
BA_ "SendType" BO_ 336 "Event";
BA_ "SendType" BO_ 333 "Event";
BA_ "SendType" BO_ 332 "Event";
BA_ "SendType" BO_ 331 "Event";
BA_ "SendType" BO_ 330 "Event";
BA_ "SendType" BO_ 329 "Event";
BA_ "SendType" BO_ 325 "Event";
BA_ "SendType" BO_ 321 "Event";
BA_ "SendType" BO_ 320 "Event";
BA_ "GenMsgCycleTime" BO_ 313 20;
BA_ "RxTimeoutMs" BO_ 313 60;
BA_ "MoTeC" BO_ 313 "Yes";
BA_ "SendType" BO_ 312 "Event";
BA_ "GenMsgCycleTime" BO_ 311 20;
BA_ "RxTimeoutMs" BO_ 311 60;
BA_ "MoTeC" BO_ 311 "Yes";
BA_ "SendType" BO_ 310 "Event";
BA_ "GenMsgCycleTime" BO_ 309 100;
BA_ "RxTimeoutMs" BO_ 309 300;
BA_ "MoTeC" BO_ 309 "Yes";
BA_ "GenMsgCycleTime" BO_ 308 100;
BA_ "RxTimeoutMs" BO_ 308 300;
BA_ "MoTeC" BO_ 308 "Yes";
BA_ "SendType" BO_ 307 "Event";
BA_ "GenMsgCycleTime" BO_ 306 20;
BA_ "RxTimeoutMs" BO_ 306 60;
BA_ "MoTeC" BO_ 306 "Yes";
BA_ "SendType" BO_ 305 "Event";
BA_ "GenMsgCycleTime" BO_ 304 1000;
BA_ "RxTimeoutMs" BO_ 304 3000;
BA_ "MoTeC" BO_ 304 "Yes";
BA_ "SendType" BO_ 292 "Event";
BA_ "SendType" BO_ 291 "Event";
BA_ "GenMsgCycleTime" BO_ 290 10;
BA_ "RxTimeoutMs" BO_ 290 30;
BA_ "MoTeC" BO_ 290 "Yes";
BA_ "GenMsgCycleTime" BO_ 289 10;
BA_ "RxTimeoutMs" BO_ 289 30;
BA_ "MoTeC" BO_ 289 "Yes";
BA_ "SendType" BO_ 288 "Event";
BA_ "SendType" BO_ 273 "Event";
BA_ "SendType" BO_ 272 "Event";
BA_ "SendType" BO_ 258 "Event";
BA_ "SendType" BO_ 257 "Event";
BA_ "GenMsgCycleTime" BO_ 256 1000;
BA_ "RxTimeoutMs" BO_ 256 3000;
BA_ "MoTeC" BO_ 256 "Yes";
